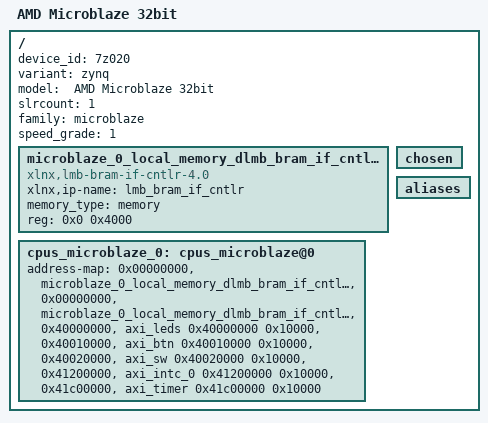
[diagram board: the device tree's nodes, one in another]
/dts-v1/;
#include "pl.dtsi"
/ {
	device_id = "7z020";
	#address-cells = <1>;
	variant = "zynq";
	model = " AMD Microblaze 32bit";
	#size-cells = <1>;
	slrcount = <1>;
	family = "microblaze";
	speed_grade = "1";
	microblaze_0_local_memory_dlmb_bram_if_cntlr_memory: memory@0 {
		ranges = <0 0x0 0x4000>;
		compatible = "xlnx,lmb-bram-if-cntlr-4.0" , "mmio-sram";
		#address-cells = <1>;
		xlnx,ip-name = "lmb_bram_if_cntlr";
		device_type = "memory";
		#size-cells = <1>;
		memory_type = "memory";
		reg = <0x0 0x4000>;
	};
	chosen {
	};
	aliases {
	};
	cpus_microblaze_0: cpus_microblaze@0 {
		address-map = <0x00000000 &microblaze_0_local_memory_dlmb_bram_if_cntlr_memory 0x00000000 0x4000>, 
			      <0x00000000 &microblaze_0_local_memory_dlmb_bram_if_cntlr 0x00000000 0x4000>, 
			      <0x40000000 &axi_leds 0x40000000 0x10000>, 
			      <0x40010000 &axi_btn 0x40010000 0x10000>, 
			      <0x40020000 &axi_sw 0x40020000 0x10000>, 
			      <0x41200000 &axi_intc_0 0x41200000 0x10000>, 
			      <0x41c00000 &axi_timer 0x41c00000 0x10000>;
		#ranges-address-cells = <0x1>;
		#ranges-size-cells = <0x1>;
	};
};
